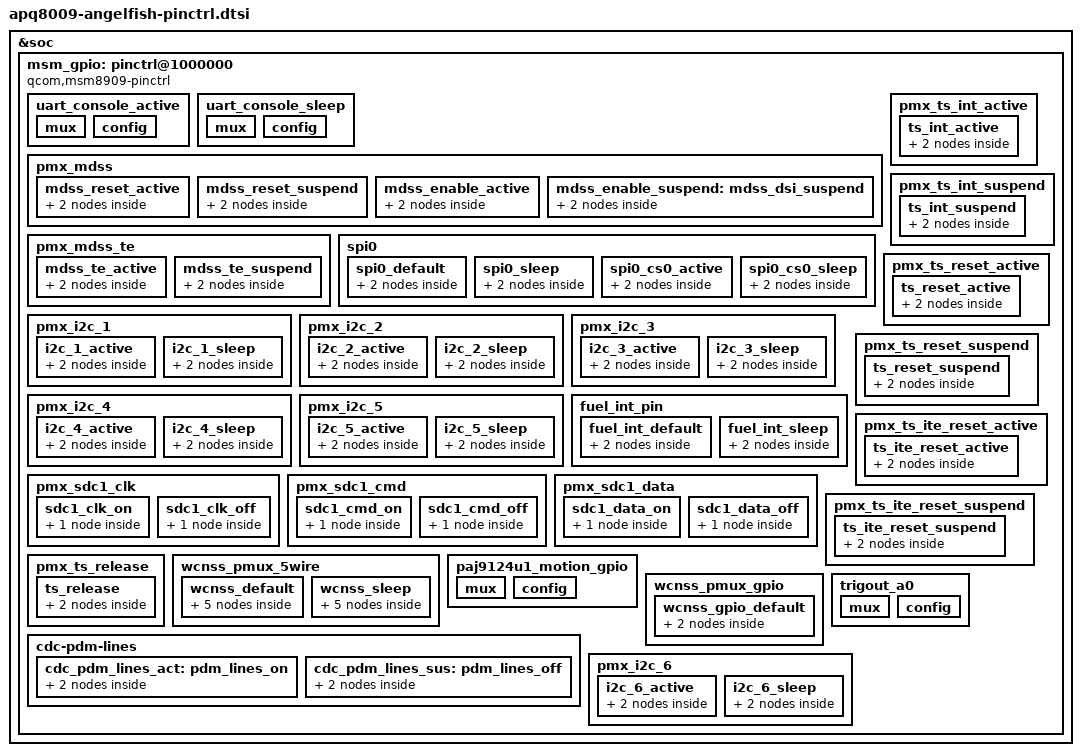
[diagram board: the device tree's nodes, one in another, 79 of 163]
/* Copyright (c) 2016, LGE Inc. All rights reserved.
 *
 * This program is free software; you can redistribute it and/or modify
 * it under the terms of the GNU General Public License version 2 and
 * only version 2 as published by the Free Software Foundation.
 *
 * This program is distributed in the hope that it will be useful,
 * but WITHOUT ANY WARRANTY; without even the implied warranty of
 * MERCHANTABILITY or FITNESS FOR A PARTICULAR PURPOSE.  See the
 * GNU General Public License for more details.
 */

&soc {
	msm_gpio: pinctrl@1000000 {
		compatible = "qcom,msm8909-pinctrl";
		reg = <0x1000000 0x300000>;
		interrupts = <0 208 0>;
		gpio-controller;
		#gpio-cells = <2>;
		interrupt-controller;
		#interrupt-cells = <2>;

		uart_console_active: uart_console_active {
			mux {
				pins = "gpio4", "gpio5";
				function = "blsp_uart1";
			};
			config {
				pins = "gpio4", "gpio5";
				drive-strength = <2>;
				bias-disable;
			};
		};
		uart_console_sleep: uart_console_sleep {
			mux {
				pins = "gpio4", "gpio5";
				function = "blsp_uart1";
			};
			config {
				pins = "gpio4", "gpio5";
				drive-strength = <2>;
				bias-pull-down;
			};
		};

		pmx_mdss {
			mdss_reset_active: mdss_reset_active {
				mux {
					pins = "gpio25";
					function = "gpio";
				};

				config {
					pins = "gpio25";
					drive-strength = <8>; /* 8 mA */
					bias-disable = <0>; /* no pull */
				};
			};

			mdss_reset_suspend: mdss_reset_suspend {
				mux {
					pins = "gpio25";
					function = "gpio";
				};

				config {
					pins = "gpio25";
					drive-strength = <2>; /* 2 mA */
					bias-pull-down; /* pull down */
				};
			};

			mdss_enable_active: mdss_enable_active {
				mux {
					pins = "gpio38";
					function = "gpio";
				};

				config {
					pins = "gpio38";
					drive-strength = <8>; /* 8 mA */
					bias-disable = <0>; /* no pull */
					output-high;
				};
			};

			mdss_enable_suspend: mdss_dsi_suspend {
				mux {
					pins = "gpio38";
					function = "gpio";
				};

				config {
					pins = "gpio38";
					drive-strength = <2>; /* 2 mA */
					bias-pull-down; /* pull down */
					output-low;
				};
			};
		};

		pmx_mdss_te {
			mdss_te_active: mdss_te_active {
				mux {
					pins = "gpio24";
					function = "mdp_vsync";
				};

				config {
					pins = "gpio24";
					drive-strength = <2>; /* 2 mA */
					bias-pull-down; /* pull down */
				};
			};

			mdss_te_suspend: mdss_te_suspend {
				mux {
					pins = "gpio24";
					function = "mdp_vsync";
				};

				config {
					pins = "gpio24";
					drive-strength = <2>; /* 2 mA */
					bias-pull-down; /* pull down */
				};
			};
		};

		spi0 {
			spi0_default: spi0_default {
				mux {
					pins = "gpio8", "gpio9",
						"gpio11";
					function = "blsp_spi6";
				};
				config {
					pins = "gpio8", "gpio9",
						"gpio11";
					drive-strength = <12>; /* 12 MA */
					bias-disable; /* No PULL */
				};
			};
			spi0_sleep: spi0_sleep {
				mux {
					pins = "gpio8", "gpio9",
						"gpio11";
					function = "gpio";
				};
				config {
					pins = "gpio8", "gpio9",
						"gpio11";
					drive-strength = <2>; /* 2 MA */
					bias-pull-down; /* pull down */
				};
			};
			spi0_cs0_active: spi0_cs0_active {
				mux {
					pins = "gpio10";
					function = "gpio";
				};
				config {
					pins = "gpio10";
					drive-strength = <2>;
					bias-disable;
				};
			};
			spi0_cs0_sleep: spi0_cs0_sleep {
				mux {
					pins = "gpio10";
					function = "gpio";
				};
				config {
					pins = "gpio10";
					drive-strength = <2>;
					bias-disable;
				};
			};
		};

		pmx_i2c_1 {
			i2c_1_active: i2c_1_active {
				mux {
					pins = "gpio6", "gpio7";
					function = "blsp_i2c1";
				};
				config {
					pins = "gpio6", "gpio7";
					drive-strength = <2>; /* 2 MA */
					bias-disable; /* No PULL */
				};
			};
			i2c_1_sleep: i2c_1_sleep {
				mux {
					pins = "gpio6", "gpio7";
					function = "blsp_i2c1";
				};
				config {
					pins = "gpio6", "gpio7";
					drive-strength = <2>; /* 2 MA */
					bias-disable; /* No PULL */
				};
			};
		};

		pmx_i2c_2 {
			i2c_2_active: i2c_2_active {
				mux {
					pins = "gpio111", "gpio112";
					function = "blsp_i2c2";
				};
				config {
					pins = "gpio111", "gpio112";
					drive-strength = <2>; /* 2 MA */
					bias-disable; /* No PULL */
				};
			};
			i2c_2_sleep: i2c_2_sleep {
				mux {
					pins = "gpio111", "gpio112";
					function = "blsp_i2c2";
				};
				config {
					pins = "gpio111", "gpio112";
					drive-strength = <2>; /* 2 MA */
					bias-disable; /* No PULL */
				};
			};
		};

		pmx_i2c_3 {
			i2c_3_active: i2c_3_active {
				mux {
					pins = "gpio29", "gpio30";
					function = "blsp_i2c3";
				};
				config {
					pins = "gpio29", "gpio30";
					drive-strength = <2>; /* 2 MA */
					bias-disable; /* No PULL */
				};
			};
			i2c_3_sleep: i2c_3_sleep {
				mux {
					pins = "gpio29", "gpio30";
					function = "blsp_i2c3";
				};
				config {
					pins = "gpio29", "gpio30";
					drive-strength = <2>; /* 2 MA */
					bias-disable; /* No PULL */
				};
			};
		};

		pmx_i2c_4 {
			i2c_4_active: i2c_4_active {
				mux {
					pins = "gpio14", "gpio15";
					function = "blsp_i2c4";
				};
				config {
					pins = "gpio14", "gpio15";
					drive-strength = <2>; /* 2 MA */
					bias-disable; /* No PULL */
				};
			};
			i2c_4_sleep: i2c_4_sleep {
				mux {
					pins = "gpio14", "gpio15";
					function = "blsp_i2c4";
				};
				config {
					pins = "gpio14", "gpio15";
					drive-strength = <2>; /* 2 MA */
					bias-disable; /* No PULL */
				};
			};
		};

		pmx_i2c_5 {
			i2c_5_active: i2c_5_active {
				mux {
					pins = "gpio19", "gpio18";
					function = "blsp_i2c5";
				};
				config {
					pins = "gpio19", "gpio18";
					drive-strength = <2>; /* 2 MA */
					bias-disable; /* No PULL */
				};
			};
			i2c_5_sleep: i2c_5_sleep {
				mux {
					pins = "gpio19", "gpio18";
					function = "blsp_i2c5";
				};
				config {
					pins = "gpio19", "gpio18";
					drive-strength = <2>; /* 2 MA */
					bias-disable; /* No PULL */
				};
			};
		};

		fuel_int_pin {
			fuel_int_default: fuel_int_default {
				mux {
					pins = "gpio58";
					function ="gpio";
				};
				config {
					pins = "gpio58";
					drive-strength = <2>;   /* 2 MA */
					bias-pull-up;           /* PULL UP*/
				};
			};
			fuel_int_sleep: fuel_int_sleep {
				mux {
					pins = "gpio58";
					function ="gpio";
				};
				config {
					pins = "gpio58";
					drive-strength = <2>;   /* 2 MA */
					bias-pull-up;           /* PULL UP*/
				};
			};
		};

		pmx_sdc1_clk {
			sdc1_clk_on: sdc1_clk_on {
				config {
					pins = "sdc1_clk";
					bias-disable; /* NO pull */
					drive-strength = <16>; /* 16 MA */
				};
			};
			sdc1_clk_off: sdc1_clk_off {
				config {
					pins = "sdc1_clk";
					bias-disable; /* NO pull */
					drive-strength = <2>; /* 2 MA */
				};
			};
		};

		pmx_sdc1_cmd {
			sdc1_cmd_on: sdc1_cmd_on {
				config {
					pins = "sdc1_cmd";
					bias-pull-up; /* pull up */
					drive-strength = <10>; /* 10 MA */
				};
			};
			sdc1_cmd_off: sdc1_cmd_off {
				config {
					pins = "sdc1_cmd";
					bias-pull-up; /* pull up */
					drive-strength = <2>; /* 2 MA */
				};
			};
		};

		pmx_sdc1_data {
			sdc1_data_on: sdc1_data_on {
				config {
					pins = "sdc1_data";
					bias-pull-up; /* pull up */
					drive-strength = <10>; /* 10 MA */
				};
			};
			sdc1_data_off: sdc1_data_off {
				config {
					pins = "sdc1_data";
					bias-pull-up; /* pull up */
					drive-strength = <2>; /* 2 MA */
				};
			};
		};

		/* add pingrp for touchscreen */
		pmx_ts_int_active {
			ts_int_active: ts_int_active {
				mux {
					pins = "gpio13";
					function = "gpio";
				};

				config {
					pins = "gpio13";
					drive-strength = <8>;
					bias-pull-up;
				};
			};
		};

		pmx_ts_int_suspend {
			ts_int_suspend: ts_int_suspend {
				mux {
					pins = "gpio13";
					function = "gpio";
				};

				config {
					pins = "gpio13";
					drive-strength = <2>;
					bias-pull-down;
				};
			};
		};

		pmx_ts_reset_active {
			ts_reset_active: ts_reset_active {
				mux {
					pins = "gpio12";
					function = "gpio";
				};

				config {
					pins = "gpio12";
					drive-strength = <8>;
					bias-pull-up;
				};
			};
		};

		pmx_ts_reset_suspend {
			ts_reset_suspend: ts_reset_suspend {
				mux {
					pins = "gpio12";
					function = "gpio";
				};

				config {
					pins = "gpio12";
					drive-strength = <2>;
					bias-pull-down;
				};
			};
		};

		/* Pinctrl dt nodes for reset gpio for ITE tech controller */
		pmx_ts_ite_reset_active {
			ts_ite_reset_active: ts_ite_reset_active {
				mux {
					pins = "gpio12";
					function = "gpio";
				};

				config {
					pins = "gpio12";
					drive-strength = <8>;
					bias-pull-down;
					output-high;
				};
			};
		};

		pmx_ts_ite_reset_suspend {
			ts_ite_reset_suspend: ts_ite_reset_suspend {
				mux {
					pins = "gpio12";
					function = "gpio";
				};

				config {
					pins = "gpio12";
					drive-strength = <2>;
					bias-pull-down;
					output-low;
				};
			};
		};

		pmx_ts_release {
			ts_release: ts_release {
				mux {
					pins = "gpio13", "gpio12";
					function = "gpio";
				};

				config {
					pins = "gpio13", "gpio12";
					drive-strength = <2>;
					bias-pull-down;
				};
			};
		};

		wcnss_pmux_5wire {
			wcnss_default: wcnss_default {
				wcss_wlan2 {
					pins = "gpio40";
					function = "wcss_wlan2";
				};
				wcss_wlan1 {
					pins = "gpio41";
					function = "wcss_wlan1";
				};
				wcss_wlan0 {
					pins = "gpio42";
					function = "wcss_wlan0";
				};
				wcss_wlan {
					pins = "gpio43", "gpio44";
					function = "wcss_wlan";
				};
				config {
					pins = "gpio40", "gpio41",
						"gpio42", "gpio43",
						"gpio44";
					drive-strength = <6>; /* 6 MA */
					bias-pull-up; /* PULL UP */
				};
			};

			wcnss_sleep: wcnss_sleep {
				wcss_wlan2 {
					pins = "gpio40";
					function = "wcss_wlan2";
				};
				wcss_wlan1 {
					pins = "gpio41";
					function = "wcss_wlan1";
				};
				wcss_wlan0 {
					pins = "gpio42";
					function = "wcss_wlan0";
				};
				wcss_wlan {
					pins = "gpio43", "gpio44";
					function = "wcss_wlan";
				};

				config {
					pins = "gpio40", "gpio41",
						"gpio42", "gpio43",
						"gpio44";
					drive-strength = <2>; /* 2 MA */
					bias-pull-down; /* PULL Down */
				};
			};
		};

		paj9124u1_motion_gpio: paj9124u1_motion_gpio {
			mux {
				pins = "gpio95";
				function = "gpio";
			};
			config {
				pins = "gpio95";
				drive-strength = <2>;
				bias-pull-up; /* PULL UP */
			};
		};

		wcnss_pmux_gpio: wcnss_pmux_gpio {
			wcnss_gpio_default: wcnss_gpio_default {
				mux {
					pins = "gpio40", "gpio41",
						"gpio42", "gpio43",
						"gpio44";
					function = "gpio";
				};

				config {
					pins = "gpio40", "gpio41",
						"gpio42", "gpio43",
						"gpio44";
					drive-strength = <6>; /* 6 MA */
					bias-pull-up; /* PULL UP */
				};
			};
		};

		trigout_a0: trigout_a0 {
			mux {
				pins = "gpio23";
				function  = "qdss_cti_trig_out_a0";
			};

			config {
				pins = "gpio23";
				drive-strength = <2>;
				bias-disable;
			};
		};

		cdc-pdm-lines {
			cdc_pdm_lines_act: pdm_lines_on {
				mux {
					pins = "gpio59", "gpio60", "gpio61",
						"gpio62", "gpio63", "gpio64";
					function = "cdc_pdm0";
				};

				config {
					pins = "gpio59", "gpio60", "gpio61",
						"gpio62", "gpio63", "gpio64";
					drive-strength = <8>;
				};
			};
			cdc_pdm_lines_sus: pdm_lines_off {
				mux {
					pins = "gpio59", "gpio60", "gpio61",
						"gpio62", "gpio63", "gpio64";
					function = "cdc_pdm0";
				};

				config {
					pins = "gpio59", "gpio60", "gpio61",
						"gpio62", "gpio63", "gpio64";
					drive-strength = <2>;
					bias-disable;
				};
			};
		};

		pmx_i2c_6 {
			i2c_6_active: i2c_6_active {
				mux {
					pins = "gpio11", "gpio10";
					function = "blsp_i2c6";
				};
				config {
					pins = "gpio11", "gpio10";
					drive-strength = <2>; /* 2 MA */
					bias-disable; /* No PULL */
				};
			};
			i2c_6_sleep: i2c_6_sleep {
				mux {
					pins = "gpio11", "gpio10";
					function = "blsp_i2c6";
				};
				config {
					pins = "gpio11", "gpio10";
					drive-strength = <2>; /* 2 MA */
					bias-disable; /* No PULL */
				};
			};
		};
	};
};
